# nrf9220_cellrf register map
Vendor: Nordic Semiconductor; Series: nRF92; File version: 1
CPU: CM0 r0p0, little endian, no MPU, no FPU, 2 interrupt priority bits, 33 interrupts
Registers are 32-bit, read-write, reset 0x0 unless marked. A register's access mark holds for its fields unless they carry their own. Offsets are from the block's base; [hi:lo] are bit positions; 'fields as' and 'values as' point back to an identical list.

## SX (part 1 of 3) — Ahma SX register map SX register map
Base 0x46147000
0x00 TASKS_RELOADFREQINTERNAL wo — AdPllLte will reread the frequency input signal fsFreq. This task sends a unitrigger signal to AdPllLte, which can be selected from the RELOADFREQWILLTRIGGER field
  [0] TASKS_RELOADFREQINTERNAL
    1=Trigger task
0x04 TASKS_CHANGEPHASEINTERNAL wo — AdPllLte will change the phase as given by the internal AdPllLte register PHASE_CHANGE
  [0] TASKS_CHANGEPHASEINTERNAL
    1=Trigger task
0x08 TASKS_FSSENDSETTINGS wo — Send the auto-settings to AdPllLte
  [0] TASKS_FSSENDSETTINGS
    1=Trigger task
0x0C TASKS_SOFTRESET wo — Resets all the registers which are used to send configurations/trim commands to AdPllLte
  [0] TASKS_SOFTRESET
    1=Trigger task
0x10 TASKS_STARTDMA wo — Start DMA to begin the transfer of trace data into memory
  [0] TASKS_STARTDMA
    1=Trigger task
0x14 TASKS_STOPDMA wo — Stop DMA to cease the transfer of trace data into memory
  [0] TASKS_STOPDMA
    1=Trigger task
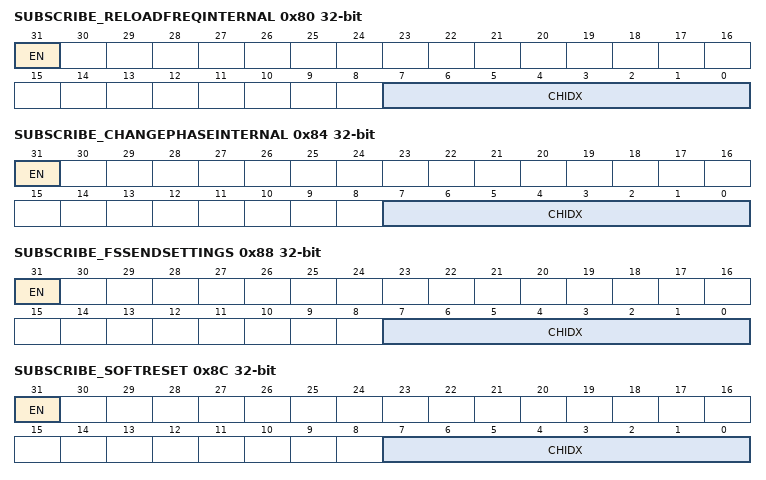
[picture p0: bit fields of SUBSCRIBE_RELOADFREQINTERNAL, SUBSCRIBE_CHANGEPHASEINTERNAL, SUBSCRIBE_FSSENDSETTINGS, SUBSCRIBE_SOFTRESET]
0x80 SUBSCRIBE_RELOADFREQINTERNAL — Subscribe configuration for task RELOADFREQINTERNAL
  [31] EN
    0=Disabled (Disable subscription); 1=Enabled (Enable subscription)
  [7:0] CHIDX — DPPI channel that task RELOADFREQINTERNAL will subscribe to
0x84 SUBSCRIBE_CHANGEPHASEINTERNAL — Subscribe configuration for task CHANGEPHASEINTERNAL
  [31] EN
    values as SUBSCRIBE_RELOADFREQINTERNAL.EN
  [7:0] CHIDX — DPPI channel that task CHANGEPHASEINTERNAL will subscribe to
0x88 SUBSCRIBE_FSSENDSETTINGS — Subscribe configuration for task FSSENDSETTINGS
  [31] EN
    values as SUBSCRIBE_RELOADFREQINTERNAL.EN
  [7:0] CHIDX — DPPI channel that task FSSENDSETTINGS will subscribe to
0x8C SUBSCRIBE_SOFTRESET — Subscribe configuration for task SOFTRESET
  [31] EN
    values as SUBSCRIBE_RELOADFREQINTERNAL.EN
  [7:0] CHIDX — DPPI channel that task SOFTRESET will subscribe to
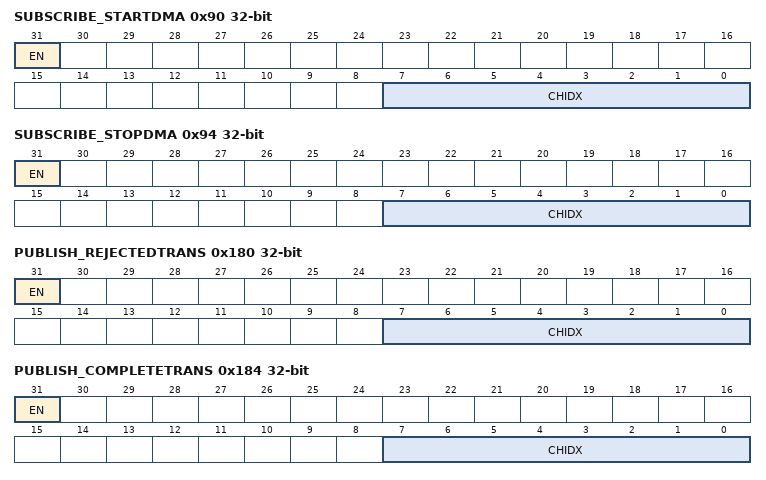
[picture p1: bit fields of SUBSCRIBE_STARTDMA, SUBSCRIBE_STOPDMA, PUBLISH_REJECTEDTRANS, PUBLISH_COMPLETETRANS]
0x90 SUBSCRIBE_STARTDMA — Subscribe configuration for task STARTDMA
  [31] EN
    values as SUBSCRIBE_RELOADFREQINTERNAL.EN
  [7:0] CHIDX — DPPI channel that task STARTDMA will subscribe to
0x94 SUBSCRIBE_STOPDMA — Subscribe configuration for task STOPDMA
  [31] EN
    values as SUBSCRIBE_RELOADFREQINTERNAL.EN
  [7:0] CHIDX — DPPI channel that task STOPDMA will subscribe to
0x100 EVENTS_REJECTEDTRANS — The command written to AdPllLte was rejected because of an ongoing transaction
  [0] EVENTS_REJECTEDTRANS
    0=NotGenerated (Event not generated); 1=Generated (Event generated)
0x104 EVENTS_COMPLETETRANS — Completed a transaction to AdPllLte successfully
  [0] EVENTS_COMPLETETRANS
    values as EVENTS_REJECTEDTRANS.EVENTS_REJECTEDTRANS
0x108 EVENTS_FAILEDTRANS — Did not successfully complete a transaction to AdPllLte (only when ENABLETIMEOUT is set in FSASYNCBUSCONF)
  [0] EVENTS_FAILEDTRANS
    values as EVENTS_REJECTEDTRANS.EVENTS_REJECTEDTRANS
0x10C EVENTS_CLOCKSTOPPEDINT — AdPllLte stopped its clock internally
  [0] EVENTS_CLOCKSTOPPEDINT
    values as EVENTS_REJECTEDTRANS.EVENTS_REJECTEDTRANS
0x110 EVENTS_COMPLETEUNITRIGGER — Unitrigger signal has successfully passed to the AdPllLte island
  [0] EVENTS_COMPLETEUNITRIGGER
    values as EVENTS_REJECTEDTRANS.EVENTS_REJECTEDTRANS
0x114 EVENTS_FAILEDUNITRIGGER — Unitrigger signal has failed to arrive in AdPllLte island (only when ENABLETIMEOUT is set in FSUNITRIGGERCONF)
  [0] EVENTS_FAILEDUNITRIGGER
    values as EVENTS_REJECTEDTRANS.EVENTS_REJECTEDTRANS
0x118 EVENTS_PLLLOCKED — AdPllLte has locked to the specified frequency
  [0] EVENTS_PLLLOCKED
    values as EVENTS_REJECTEDTRANS.EVENTS_REJECTEDTRANS
0x11C EVENTS_PLLLOCKLOST — AdPllLte has lost lock
  [0] EVENTS_PLLLOCKLOST
    values as EVENTS_REJECTEDTRANS.EVENTS_REJECTEDTRANS
0x120 EVENTS_DMAEND — DMA has filled up the result buffer in RAM.
  [0] EVENTS_DMAEND
    values as EVENTS_REJECTEDTRANS.EVENTS_REJECTEDTRANS
0x124 EVENTS_COMPLETEFSSENDSETTINGS — Sending of auto-settings to AdPllLte is successful
  [0] EVENTS_COMPLETEFSSENDSETTINGS
    values as EVENTS_REJECTEDTRANS.EVENTS_REJECTEDTRANS
0x128 EVENTS_FAILEDFSSENDSETTINGS — Sending of auto-settings to AdPlllte has failed
  [0] EVENTS_FAILEDFSSENDSETTINGS
    values as EVENTS_REJECTEDTRANS.EVENTS_REJECTEDTRANS
0x180 PUBLISH_REJECTEDTRANS — Publish configuration for event REJECTEDTRANS
  [31] EN
    0=Disabled (Disable publishing); 1=Enabled (Enable publishing)
  [7:0] CHIDX — DPPI channel that event REJECTEDTRANS will publish to
0x184 PUBLISH_COMPLETETRANS — Publish configuration for event COMPLETETRANS
  [31] EN
    values as PUBLISH_REJECTEDTRANS.EN
  [7:0] CHIDX — DPPI channel that event COMPLETETRANS will publish to
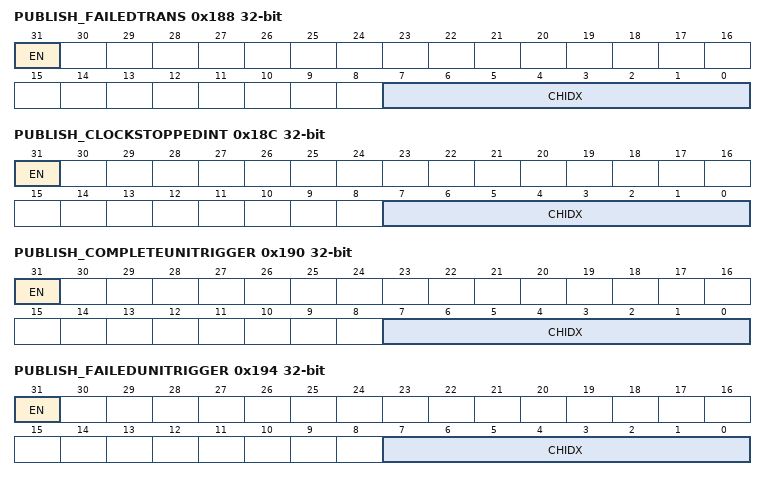
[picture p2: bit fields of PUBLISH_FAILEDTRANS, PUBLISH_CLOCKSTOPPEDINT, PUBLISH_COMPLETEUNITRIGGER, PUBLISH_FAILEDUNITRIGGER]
0x188 PUBLISH_FAILEDTRANS — Publish configuration for event FAILEDTRANS
  [31] EN
    values as PUBLISH_REJECTEDTRANS.EN
  [7:0] CHIDX — DPPI channel that event FAILEDTRANS will publish to
0x18C PUBLISH_CLOCKSTOPPEDINT — Publish configuration for event CLOCKSTOPPEDINT
  [31] EN
    values as PUBLISH_REJECTEDTRANS.EN
  [7:0] CHIDX — DPPI channel that event CLOCKSTOPPEDINT will publish to
0x190 PUBLISH_COMPLETEUNITRIGGER — Publish configuration for event COMPLETEUNITRIGGER
  [31] EN
    values as PUBLISH_REJECTEDTRANS.EN
  [7:0] CHIDX — DPPI channel that event COMPLETEUNITRIGGER will publish to
0x194 PUBLISH_FAILEDUNITRIGGER — Publish configuration for event FAILEDUNITRIGGER
  [31] EN
    values as PUBLISH_REJECTEDTRANS.EN
  [7:0] CHIDX — DPPI channel that event FAILEDUNITRIGGER will publish to
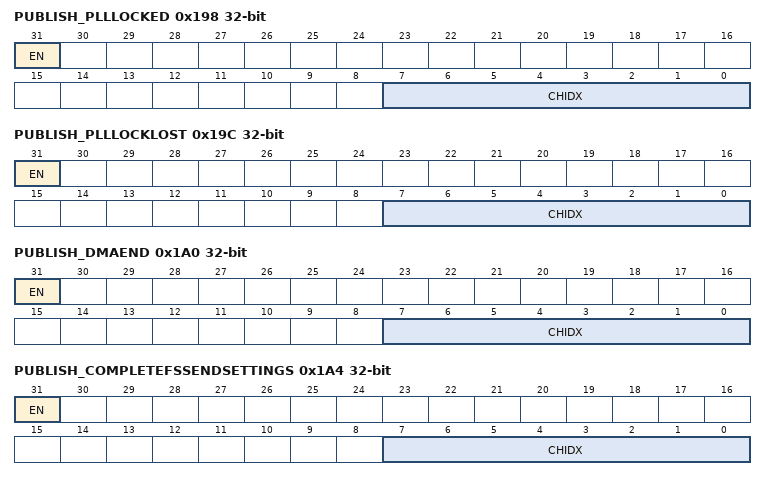
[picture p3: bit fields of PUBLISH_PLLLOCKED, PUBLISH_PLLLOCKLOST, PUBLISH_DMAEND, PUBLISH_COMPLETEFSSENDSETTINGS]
0x198 PUBLISH_PLLLOCKED — Publish configuration for event PLLLOCKED
  [31] EN
    values as PUBLISH_REJECTEDTRANS.EN
  [7:0] CHIDX — DPPI channel that event PLLLOCKED will publish to
0x19C PUBLISH_PLLLOCKLOST — Publish configuration for event PLLLOCKLOST
  [31] EN
    values as PUBLISH_REJECTEDTRANS.EN
  [7:0] CHIDX — DPPI channel that event PLLLOCKLOST will publish to
0x1A0 PUBLISH_DMAEND — Publish configuration for event DMAEND
  [31] EN
    values as PUBLISH_REJECTEDTRANS.EN
  [7:0] CHIDX — DPPI channel that event DMAEND will publish to
0x1A4 PUBLISH_COMPLETEFSSENDSETTINGS — Publish configuration for event COMPLETEFSSENDSETTINGS
  [31] EN
    values as PUBLISH_REJECTEDTRANS.EN
  [7:0] CHIDX — DPPI channel that event COMPLETEFSSENDSETTINGS will publish to
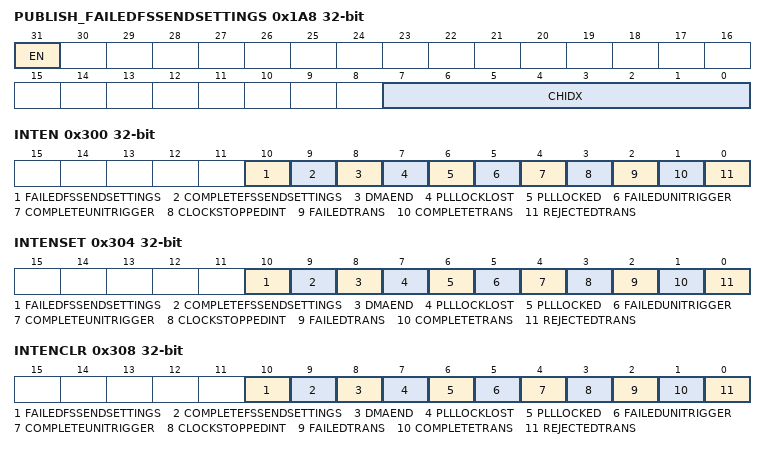
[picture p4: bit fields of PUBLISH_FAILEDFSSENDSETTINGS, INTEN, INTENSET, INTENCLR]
0x1A8 PUBLISH_FAILEDFSSENDSETTINGS — Publish configuration for event FAILEDFSSENDSETTINGS
  [31] EN
    values as PUBLISH_REJECTEDTRANS.EN
  [7:0] CHIDX — DPPI channel that event FAILEDFSSENDSETTINGS will publish to
0x300 INTEN — Enable or disable interrupt
  [all] fields
    0=Disabled; 1=Enabled
  [10] FAILEDFSSENDSETTINGS — Enable or disable interrupt for event FAILEDFSSENDSETTINGS
  [9] COMPLETEFSSENDSETTINGS — Enable or disable interrupt for event COMPLETEFSSENDSETTINGS
  [8] DMAEND — Enable or disable interrupt for event DMAEND
  [7] PLLLOCKLOST — Enable or disable interrupt for event PLLLOCKLOST
  [6] PLLLOCKED — Enable or disable interrupt for event PLLLOCKED
  [5] FAILEDUNITRIGGER — Enable or disable interrupt for event FAILEDUNITRIGGER
  [4] COMPLETEUNITRIGGER — Enable or disable interrupt for event COMPLETEUNITRIGGER
  [3] CLOCKSTOPPEDINT — Enable or disable interrupt for event CLOCKSTOPPEDINT
  [2] FAILEDTRANS — Enable or disable interrupt for event FAILEDTRANS
  [1] COMPLETETRANS — Enable or disable interrupt for event COMPLETETRANS
  [0] REJECTEDTRANS — Enable or disable interrupt for event REJECTEDTRANS
0x304 INTENSET — Enable interrupt
  [all] fields
    on read: 0=Disabled (Read: Disabled); 1=Enabled (Read: Enabled) | on write: 1=Set (Enable)
  [10] FAILEDFSSENDSETTINGS — Write '1' to enable interrupt for event FAILEDFSSENDSETTINGS
  [9] COMPLETEFSSENDSETTINGS — Write '1' to enable interrupt for event COMPLETEFSSENDSETTINGS
  [8] DMAEND — Write '1' to enable interrupt for event DMAEND
  [7] PLLLOCKLOST — Write '1' to enable interrupt for event PLLLOCKLOST
  [6] PLLLOCKED — Write '1' to enable interrupt for event PLLLOCKED
  [5] FAILEDUNITRIGGER — Write '1' to enable interrupt for event FAILEDUNITRIGGER
  [4] COMPLETEUNITRIGGER — Write '1' to enable interrupt for event COMPLETEUNITRIGGER
  [3] CLOCKSTOPPEDINT — Write '1' to enable interrupt for event CLOCKSTOPPEDINT
  [2] FAILEDTRANS — Write '1' to enable interrupt for event FAILEDTRANS
  [1] COMPLETETRANS — Write '1' to enable interrupt for event COMPLETETRANS
  [0] REJECTEDTRANS — Write '1' to enable interrupt for event REJECTEDTRANS
0x308 INTENCLR — Disable interrupt
  [all] fields
    on read: 0=Disabled (Read: Disabled); 1=Enabled (Read: Enabled) | on write: 1=Clear (Disable)
  [10] FAILEDFSSENDSETTINGS — Write '1' to disable interrupt for event FAILEDFSSENDSETTINGS
  [9] COMPLETEFSSENDSETTINGS — Write '1' to disable interrupt for event COMPLETEFSSENDSETTINGS
  [8] DMAEND — Write '1' to disable interrupt for event DMAEND
  [7] PLLLOCKLOST — Write '1' to disable interrupt for event PLLLOCKLOST
  [6] PLLLOCKED — Write '1' to disable interrupt for event PLLLOCKED
  [5] FAILEDUNITRIGGER — Write '1' to disable interrupt for event FAILEDUNITRIGGER
  [4] COMPLETEUNITRIGGER — Write '1' to disable interrupt for event COMPLETEUNITRIGGER
  [3] CLOCKSTOPPEDINT — Write '1' to disable interrupt for event CLOCKSTOPPEDINT
  [2] FAILEDTRANS — Write '1' to disable interrupt for event FAILEDTRANS
  [1] COMPLETETRANS — Write '1' to disable interrupt for event COMPLETETRANS
  [0] REJECTEDTRANS — Write '1' to disable interrupt for event REJECTEDTRANS
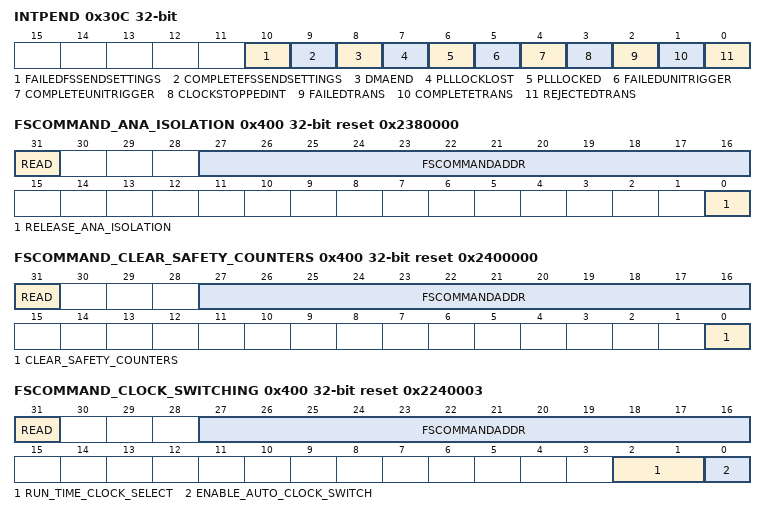
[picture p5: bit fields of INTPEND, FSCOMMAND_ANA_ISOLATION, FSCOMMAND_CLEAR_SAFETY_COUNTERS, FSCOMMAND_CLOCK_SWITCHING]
0x30C INTPEND ro — Pending interrupts
  [all] fields
    on read: 0=NotPending (Read: Not pending); 1=Pending (Read: Pending)
  [10] FAILEDFSSENDSETTINGS — Read pending status of interrupt for event FAILEDFSSENDSETTINGS
  [9] COMPLETEFSSENDSETTINGS — Read pending status of interrupt for event COMPLETEFSSENDSETTINGS
  [8] DMAEND — Read pending status of interrupt for event DMAEND
  [7] PLLLOCKLOST — Read pending status of interrupt for event PLLLOCKLOST
  [6] PLLLOCKED — Read pending status of interrupt for event PLLLOCKED
  [5] FAILEDUNITRIGGER — Read pending status of interrupt for event FAILEDUNITRIGGER
  [4] COMPLETEUNITRIGGER — Read pending status of interrupt for event COMPLETEUNITRIGGER
  [3] CLOCKSTOPPEDINT — Read pending status of interrupt for event CLOCKSTOPPEDINT
  [2] FAILEDTRANS — Read pending status of interrupt for event FAILEDTRANS
  [1] COMPLETETRANS — Read pending status of interrupt for event COMPLETETRANS
  [0] REJECTEDTRANS — Read pending status of interrupt for event REJECTEDTRANS
0x400 FSCOMMAND_ANA_ISOLATION reset 0x2380000 — Send or receive command directly to/from the AdPllLte digital island. Only write to this register when FSASYNCBUSBUSY returns 0
  [31] READ — When 1, a read transaction is initiated. When the event COMPLETETRANS is set, read back this register
  [27:16] FSCOMMANDADDR — Address for the async interface. ALWAYS 0x238.
    0x238=ANA_ISOLATION_ADDR (ALWAYS 0x238.)
  [0] RELEASE_ANA_ISOLATION — When set to 1, we drop the isolation of signals from the analog side EVEN WHEN fsStart is low
0x400 FSCOMMAND_CLEAR_SAFETY_COUNTERS reset 0x2400000 (alternate view of FSCOMMAND_ANA_ISOLATION) — Send or receive command directly to/from the AdPllLte digital island. Only write to this register when FSASYNCBUSBUSY returns 0
  [31] READ — When 1, a read transaction is initiated. When the event COMPLETETRANS is set, read back this register
  [27:16] FSCOMMANDADDR — Address for the async interface. ALWAYS 0x240.
    0x240=CLEAR_SAFETY_COUNTERS_ADDR (ALWAYS 0x240.)
  [0] CLEAR_SAFETY_COUNTERS — Clear the safety counters
0x400 FSCOMMAND_CLOCK_SWITCHING reset 0x2240003 (alternate view of FSCOMMAND_ANA_ISOLATION) — Send or receive command directly to/from the AdPllLte digital island. Only write to this register when FSASYNCBUSBUSY returns 0
  [31] READ — When 1, a read transaction is initiated. When the event COMPLETETRANS is set, read back this register
  [27:16] FSCOMMANDADDR — Address for the async interface. ALWAYS 0x224.
    0x224=CLOCK_SWITCHING_ADDR (ALWAYS 0x224.)
  [2:1] RUN_TIME_CLOCK_SELECT — Clock select for PLL runtime. 0:ck64MCore, 1:ckRetimed, 2: ckRef
  [0] ENABLE_AUTO_CLOCK_SWITCH — Enable automatic switching from ck64MCore to configurable run time clock and back
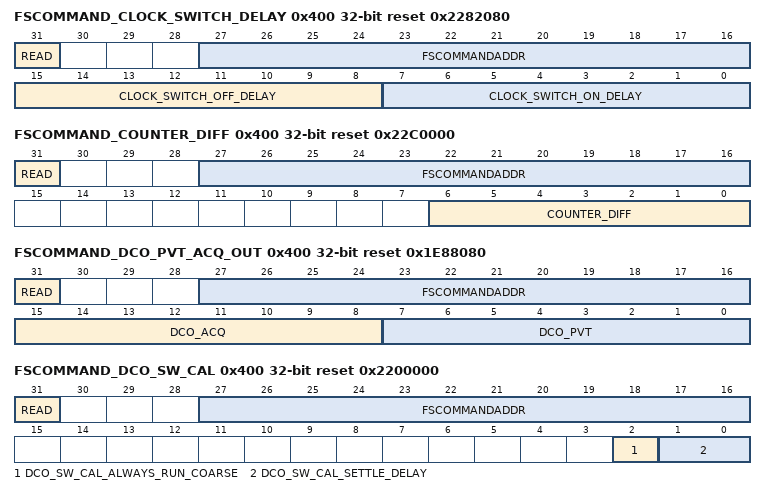
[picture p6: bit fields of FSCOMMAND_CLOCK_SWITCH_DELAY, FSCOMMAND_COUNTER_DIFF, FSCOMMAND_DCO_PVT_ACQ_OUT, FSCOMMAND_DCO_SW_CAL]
0x400 FSCOMMAND_CLOCK_SWITCH_DELAY reset 0x2282080 (alternate view of FSCOMMAND_ANA_ISOLATION) — Send or receive command directly to/from the AdPllLte digital island. Only write to this register when FSASYNCBUSBUSY returns 0
  [31] READ — When 1, a read transaction is initiated. When the event COMPLETETRANS is set, read back this register
  [27:16] FSCOMMANDADDR — Address for the async interface. ALWAYS 0x228.
    0x228=CLOCK_SWITCH_DELAY_ADDR (ALWAYS 0x228.)
  [15:8] CLOCK_SWITCH_OFF_DELAY — Number of clock cycles to wait before shutting down DCO before and switching to ck64MCore clock
  [7:0] CLOCK_SWITCH_ON_DELAY — Number of clock cycles to wait after swing calibration state before switching to ckRetimed clock
0x400 FSCOMMAND_COUNTER_DIFF reset 0x22C0000 (alternate view of FSCOMMAND_ANA_ISOLATION) — Send or receive command directly to/from the AdPllLte digital island. Only write to this register when FSASYNCBUSBUSY returns 0
  [31] READ — When 1, a read transaction is initiated. When the event COMPLETETRANS is set, read back this register
  [27:16] FSCOMMANDADDR — Address for the async interface. ALWAYS 0x22C.
    0x22C=COUNTER_DIFF_ADDR (ALWAYS 0x22C.)
  [6:0] COUNTER_DIFF — The current diff in the counter phase detect module. This number is proportional with the DCO frequency
0x400 FSCOMMAND_DCO_PVT_ACQ_OUT reset 0x1E88080 (alternate view of FSCOMMAND_ANA_ISOLATION) — Send or receive command directly to/from the AdPllLte digital island. Only write to this register when FSASYNCBUSBUSY returns 0
  [31] READ — When 1, a read transaction is initiated. When the event COMPLETETRANS is set, read back this register
  [27:16] FSCOMMANDADDR — Address for the async interface. ALWAYS 0x1E8.
    0x1E8=DCO_PVT_ACQ_OUT_ADDR (ALWAYS 0x1E8.)
  [15:8] DCO_ACQ — Read the current ACQ bank control word
  [7:0] DCO_PVT — Read the current PVT bank control word
0x400 FSCOMMAND_DCO_SW_CAL reset 0x2200000 (alternate view of FSCOMMAND_ANA_ISOLATION) — Send or receive command directly to/from the AdPllLte digital island. Only write to this register when FSASYNCBUSBUSY returns 0
  [31] READ — When 1, a read transaction is initiated. When the event COMPLETETRANS is set, read back this register
  [27:16] FSCOMMANDADDR — Address for the async interface. ALWAYS 0x220.
    0x220=DCO_SW_CAL_ADDR (ALWAYS 0x220.)
  [2] DCO_SW_CAL_ALWAYS_RUN_COARSE — Always rerun coarse swing calibration before fine swing calibration
  [1:0] DCO_SW_CAL_SETTLE_DELAY — DCO swing calibration settling delay after calibration value is updated
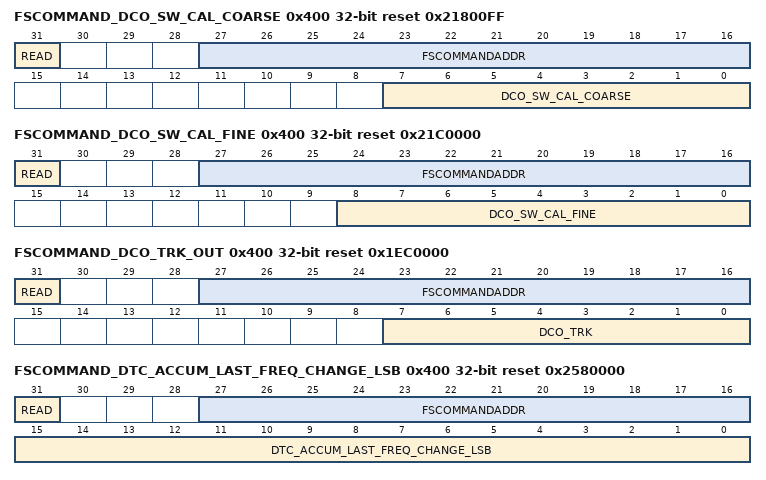
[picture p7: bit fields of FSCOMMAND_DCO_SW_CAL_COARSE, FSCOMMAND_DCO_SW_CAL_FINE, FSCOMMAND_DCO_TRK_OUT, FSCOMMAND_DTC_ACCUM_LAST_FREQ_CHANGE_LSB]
0x400 FSCOMMAND_DCO_SW_CAL_COARSE reset 0x21800FF (alternate view of FSCOMMAND_ANA_ISOLATION) — Send or receive command directly to/from the AdPllLte digital island. Only write to this register when FSASYNCBUSBUSY returns 0
  [31] READ — When 1, a read transaction is initiated. When the event COMPLETETRANS is set, read back this register
  [27:16] FSCOMMANDADDR — Address for the async interface. ALWAYS 0x218.
    0x218=DCO_SW_CAL_COARSE_ADDR (ALWAYS 0x218.)
  [7:0] DCO_SW_CAL_COARSE — The current DCO swing coarse calibration value
0x400 FSCOMMAND_DCO_SW_CAL_FINE reset 0x21C0000 (alternate view of FSCOMMAND_ANA_ISOLATION) — Send or receive command directly to/from the AdPllLte digital island. Only write to this register when FSASYNCBUSBUSY returns 0
  [31] READ — When 1, a read transaction is initiated. When the event COMPLETETRANS is set, read back this register
  [27:16] FSCOMMANDADDR — Address for the async interface. ALWAYS 0x21C.
    0x21C=DCO_SW_CAL_FINE_ADDR (ALWAYS 0x21C.)
  [8:0] DCO_SW_CAL_FINE — The current DCO swing fine calibration value
0x400 FSCOMMAND_DCO_TRK_OUT reset 0x1EC0000 (alternate view of FSCOMMAND_ANA_ISOLATION) — Send or receive command directly to/from the AdPllLte digital island. Only write to this register when FSASYNCBUSBUSY returns 0
  [31] READ — When 1, a read transaction is initiated. When the event COMPLETETRANS is set, read back this register
  [27:16] FSCOMMANDADDR — Address for the async interface. ALWAYS 0x1EC.
    0x1EC=DCO_TRK_OUT_ADDR (ALWAYS 0x1EC.)
  [7:0] DCO_TRK — Read the current TRK bank control word
0x400 FSCOMMAND_DTC_ACCUM_LAST_FREQ_CHANGE_LSB reset 0x2580000 (alternate view of FSCOMMAND_ANA_ISOLATION) — Send or receive command directly to/from the AdPllLte digital island. Only write to this register when FSASYNCBUSBUSY returns 0
  [31] READ — When 1, a read transaction is initiated. When the event COMPLETETRANS is set, read back this register
  [27:16] FSCOMMANDADDR — Address for the async interface. ALWAYS 0x258.
    0x258=DTC_ACCUM_LAST_FREQ_CHANGE_LSB_ADDR (ALWAYS 0x258.)
  [15:0] DTC_ACCUM_LAST_FREQ_CHANGE_LSB — The accumulator value the last time the frequency was changed or when SAMPLE_DTC_ACCUM_NOW is written to
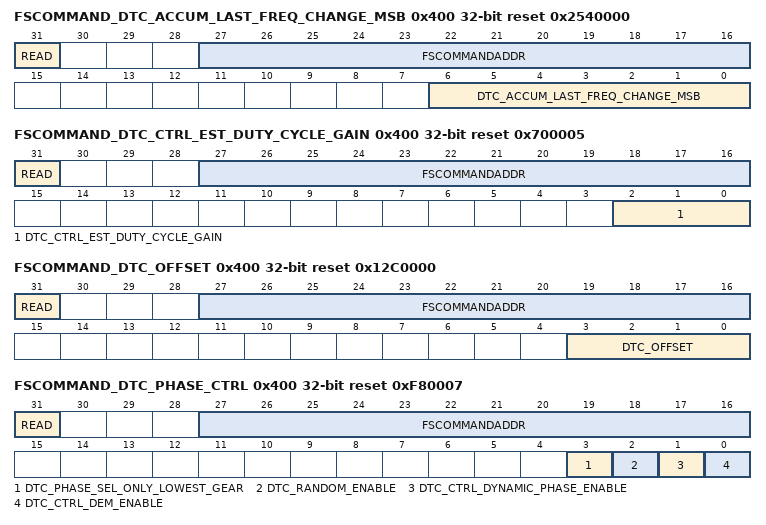
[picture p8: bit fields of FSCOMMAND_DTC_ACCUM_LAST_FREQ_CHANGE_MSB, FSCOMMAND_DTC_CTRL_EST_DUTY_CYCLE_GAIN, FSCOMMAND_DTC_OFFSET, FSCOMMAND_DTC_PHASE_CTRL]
0x400 FSCOMMAND_DTC_ACCUM_LAST_FREQ_CHANGE_MSB reset 0x2540000 (alternate view of FSCOMMAND_ANA_ISOLATION) — Send or receive command directly to/from the AdPllLte digital island. Only write to this register when FSASYNCBUSBUSY returns 0
  [31] READ — When 1, a read transaction is initiated. When the event COMPLETETRANS is set, read back this register
  [27:16] FSCOMMANDADDR — Address for the async interface. ALWAYS 0x254.
    0x254=DTC_ACCUM_LAST_FREQ_CHANGE_MSB_ADDR (ALWAYS 0x254.)
  [6:0] DTC_ACCUM_LAST_FREQ_CHANGE_MSB — The accumulator value the last time the frequency was changed or when SAMPLE_DTC_ACCUM_NOW is written to
0x400 FSCOMMAND_DTC_CTRL_EST_DUTY_CYCLE_GAIN reset 0x700005 (alternate view of FSCOMMAND_ANA_ISOLATION) — Send or receive command directly to/from the AdPllLte digital island. Only write to this register when FSASYNCBUSBUSY returns 0
  [31] READ — When 1, a read transaction is initiated. When the event COMPLETETRANS is set, read back this register
  [27:16] FSCOMMANDADDR — Address for the async interface. ALWAYS 0x70.
    112=DTC_CTRL_EST_DUTY_CYCLE_GAIN_ADDR (ALWAYS 0x70.)
  [2:0] DTC_CTRL_EST_DUTY_CYCLE_GAIN — How much impact the estimated duty cycle gain should have on the DTC compensation (shifted by this value to the left). Used in DtcComp
0x400 FSCOMMAND_DTC_OFFSET reset 0x12C0000 (alternate view of FSCOMMAND_ANA_ISOLATION) — Send or receive command directly to/from the AdPllLte digital island. Only write to this register when FSASYNCBUSBUSY returns 0
  [31] READ — When 1, a read transaction is initiated. When the event COMPLETETRANS is set, read back this register
  [27:16] FSCOMMANDADDR — Address for the async interface. ALWAYS 0x12C.
    0x12C=DTC_OFFSET_ADDR (ALWAYS 0x12C.)
  [3:0] DTC_OFFSET — Add an offset to the DTC control value
0x400 FSCOMMAND_DTC_PHASE_CTRL reset 0xF80007 (alternate view of FSCOMMAND_ANA_ISOLATION) — Send or receive command directly to/from the AdPllLte digital island. Only write to this register when FSASYNCBUSBUSY returns 0
  [31] READ — When 1, a read transaction is initiated. When the event COMPLETETRANS is set, read back this register
  [27:16] FSCOMMANDADDR — Address for the async interface. ALWAYS 0xF8.
    248=DTC_PHASE_CTRL_ADDR (ALWAYS 0xF8.)
  [3] DTC_PHASE_SEL_ONLY_LOWEST_GEAR — Phase select randomization begins only when TRK uses the lowest gear.
  [2] DTC_RANDOM_ENABLE — Enable randomization of the phase selected from the MUX following the divider.
  [1] DTC_CTRL_DYNAMIC_PHASE_ENABLE — Selects whether the DCO phase should be alternated or not. If 0, neither randomized shift and predictable shift happens. If 1, and dtcRandomEnable == 0, it alternates regularly between the two phases
  [0] DTC_CTRL_DEM_ENABLE — For enabling dynamic element matching. Used in DtcCtrl/DtcDem
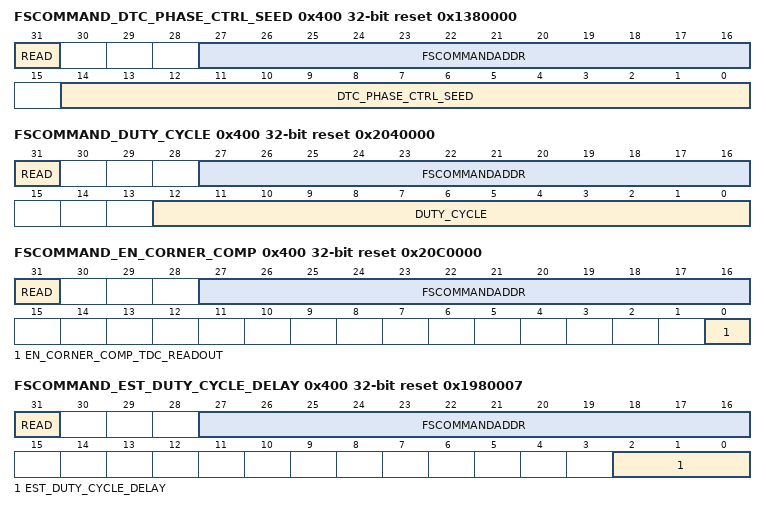
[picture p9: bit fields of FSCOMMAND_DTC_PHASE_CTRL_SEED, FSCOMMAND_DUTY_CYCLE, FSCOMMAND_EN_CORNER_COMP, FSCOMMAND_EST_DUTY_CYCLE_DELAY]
0x400 FSCOMMAND_DTC_PHASE_CTRL_SEED reset 0x1380000 (alternate view of FSCOMMAND_ANA_ISOLATION) — Send or receive command directly to/from the AdPllLte digital island. Only write to this register when FSASYNCBUSBUSY returns 0
  [31] READ — When 1, a read transaction is initiated. When the event COMPLETETRANS is set, read back this register
  [27:16] FSCOMMANDADDR — Address for the async interface. ALWAYS 0x138.
    0x138=DTC_PHASE_CTRL_SEED_ADDR (ALWAYS 0x138.)
  [14:0] DTC_PHASE_CTRL_SEED — The LFSR seed value for DtcPhaseCtrl
0x400 FSCOMMAND_DUTY_CYCLE reset 0x2040000 (alternate view of FSCOMMAND_ANA_ISOLATION) — Send or receive command directly to/from the AdPllLte digital island. Only write to this register when FSASYNCBUSBUSY returns 0
  [31] READ — When 1, a read transaction is initiated. When the event COMPLETETRANS is set, read back this register
  [27:16] FSCOMMANDADDR — Address for the async interface. ALWAYS 0x204.
    0x204=DUTY_CYCLE_ADDR (ALWAYS 0x204.)
  [12:0] DUTY_CYCLE — Read the current duty cycle estimate
0x400 FSCOMMAND_EN_CORNER_COMP reset 0x20C0000 (alternate view of FSCOMMAND_ANA_ISOLATION) — Send or receive command directly to/from the AdPllLte digital island. Only write to this register when FSASYNCBUSBUSY returns 0
  [31] READ — When 1, a read transaction is initiated. When the event COMPLETETRANS is set, read back this register
  [27:16] FSCOMMANDADDR — Address for the async interface. ALWAYS 0x20C.
    0x20C=EN_CORNER_COMP_ADDR (ALWAYS 0x20C.)
  [0] EN_CORNER_COMP_TDC_READOUT — Enable corner compensation for the loopGain for the TRK bank control (based on PVT control value relative to expected)
0x400 FSCOMMAND_EST_DUTY_CYCLE_DELAY reset 0x1980007 (alternate view of FSCOMMAND_ANA_ISOLATION) — Send or receive command directly to/from the AdPllLte digital island. Only write to this register when FSASYNCBUSBUSY returns 0
  [31] READ — When 1, a read transaction is initiated. When the event COMPLETETRANS is set, read back this register
  [27:16] FSCOMMANDADDR — Address for the async interface. ALWAYS 0x198.
    0x198=EST_DUTY_CYCLE_DELAY_ADDR (ALWAYS 0x198.)
  [2:0] EST_DUTY_CYCLE_DELAY — How many cycles to delay i_s_phase_edge and i_s_dtc_sign at the input of the duty-cycle estimation module
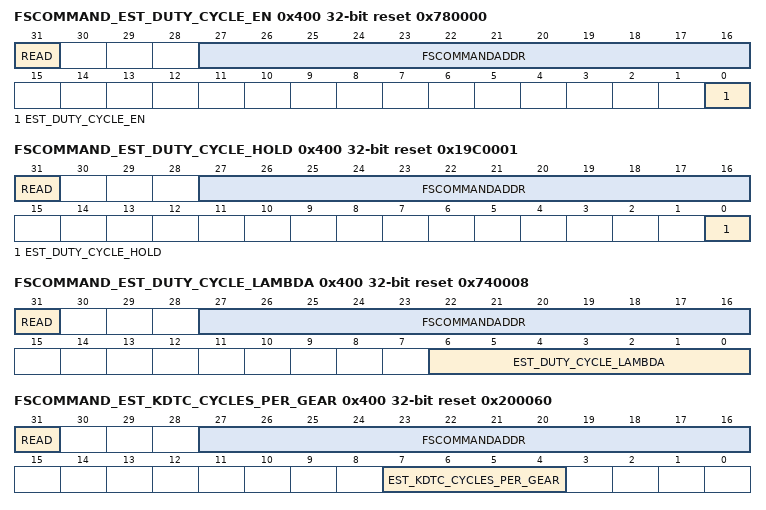
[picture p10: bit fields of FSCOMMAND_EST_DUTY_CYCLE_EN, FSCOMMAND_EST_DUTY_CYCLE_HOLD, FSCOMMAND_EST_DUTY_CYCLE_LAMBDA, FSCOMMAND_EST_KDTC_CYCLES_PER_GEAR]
0x400 FSCOMMAND_EST_DUTY_CYCLE_EN reset 0x780000 (alternate view of FSCOMMAND_ANA_ISOLATION) — Send or receive command directly to/from the AdPllLte digital island. Only write to this register when FSASYNCBUSBUSY returns 0
  [31] READ — When 1, a read transaction is initiated. When the event COMPLETETRANS is set, read back this register
  [27:16] FSCOMMANDADDR — Address for the async interface. ALWAYS 0x78.
    120=EST_DUTY_CYCLE_EN_ADDR (ALWAYS 0x78.)
  [0] EST_DUTY_CYCLE_EN — Enable duty cycle calibration. When 0, we do not compensate anything in DtcCtrl
0x400 FSCOMMAND_EST_DUTY_CYCLE_HOLD reset 0x19C0001 (alternate view of FSCOMMAND_ANA_ISOLATION) — Send or receive command directly to/from the AdPllLte digital island. Only write to this register when FSASYNCBUSBUSY returns 0
  [31] READ — When 1, a read transaction is initiated. When the event COMPLETETRANS is set, read back this register
  [27:16] FSCOMMANDADDR — Address for the async interface. ALWAYS 0x19C.
    0x19C=EST_DUTY_CYCLE_HOLD_ADDR (ALWAYS 0x19C.)
  [0] EST_DUTY_CYCLE_HOLD — Whether to remember the duty-cycle estimation value from one procedure to the next. (provided that the asynchronous reset is not set)
0x400 FSCOMMAND_EST_DUTY_CYCLE_LAMBDA reset 0x740008 (alternate view of FSCOMMAND_ANA_ISOLATION) — Send or receive command directly to/from the AdPllLte digital island. Only write to this register when FSASYNCBUSBUSY returns 0
  [31] READ — When 1, a read transaction is initiated. When the event COMPLETETRANS is set, read back this register
  [27:16] FSCOMMANDADDR — Address for the async interface. ALWAYS 0x74.
    116=EST_DUTY_CYCLE_LAMBDA_ADDR (ALWAYS 0x74.)
  [6:0] EST_DUTY_CYCLE_LAMBDA — The alpha value for the IIR filter in EstDutycycle
0x400 FSCOMMAND_EST_KDTC_CYCLES_PER_GEAR reset 0x200060 (alternate view of FSCOMMAND_ANA_ISOLATION) — Send or receive command directly to/from the AdPllLte digital island. Only write to this register when FSASYNCBUSBUSY returns 0
  [31] READ — When 1, a read transaction is initiated. When the event COMPLETETRANS is set, read back this register
  [27:16] FSCOMMANDADDR — Address for the async interface. ALWAYS 0x20.
    32=EST_KDTC_CYCLES_PER_GEAR_ADDR (ALWAYS 0x20.)
  [7:4] EST_KDTC_CYCLES_PER_GEAR — Number of cycles to be at one gear setting in EstKdtc (multiplied by 16)
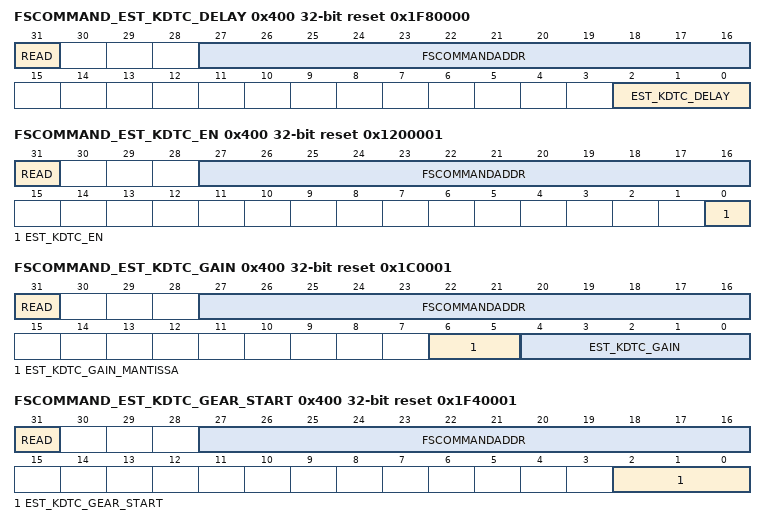
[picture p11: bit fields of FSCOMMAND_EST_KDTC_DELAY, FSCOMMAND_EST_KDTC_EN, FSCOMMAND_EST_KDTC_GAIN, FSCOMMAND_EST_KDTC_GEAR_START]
0x400 FSCOMMAND_EST_KDTC_DELAY reset 0x1F80000 (alternate view of FSCOMMAND_ANA_ISOLATION) — Send or receive command directly to/from the AdPllLte digital island. Only write to this register when FSASYNCBUSBUSY returns 0
  [31] READ — When 1, a read transaction is initiated. When the event COMPLETETRANS is set, read back this register
  [27:16] FSCOMMANDADDR — Address for the async interface. ALWAYS 0x1F8.
    0x1F8=EST_KDTC_DELAY_ADDR (ALWAYS 0x1F8.)
  [2:0] EST_KDTC_DELAY — Delay of phr_frac to align with phe_frac
0x400 FSCOMMAND_EST_KDTC_EN reset 0x1200001 (alternate view of FSCOMMAND_ANA_ISOLATION) — Send or receive command directly to/from the AdPllLte digital island. Only write to this register when FSASYNCBUSBUSY returns 0
  [31] READ — When 1, a read transaction is initiated. When the event COMPLETETRANS is set, read back this register
  [27:16] FSCOMMANDADDR — Address for the async interface. ALWAYS 0x120.
    0x120=EST_KDTC_EN_ADDR (ALWAYS 0x120.)
  [0] EST_KDTC_EN — Enable estimation of kDTC
0x400 FSCOMMAND_EST_KDTC_GAIN reset 0x1C0001 (alternate view of FSCOMMAND_ANA_ISOLATION) — Send or receive command directly to/from the AdPllLte digital island. Only write to this register when FSASYNCBUSBUSY returns 0
  [31] READ — When 1, a read transaction is initiated. When the event COMPLETETRANS is set, read back this register
  [27:16] FSCOMMANDADDR — Address for the async interface. ALWAYS 0x1C.
    28=EST_KDTC_GAIN_ADDR (ALWAYS 0x1C.)
  [6:5] EST_KDTC_GAIN_MANTISSA — The gain in the estimator loop for kDTC. Used in EstKdtc only
  [4:0] EST_KDTC_GAIN — The gain in the estimator loop for kDTC. Used in EstKdtc only
0x400 FSCOMMAND_EST_KDTC_GEAR_START reset 0x1F40001 (alternate view of FSCOMMAND_ANA_ISOLATION) — Send or receive command directly to/from the AdPllLte digital island. Only write to this register when FSASYNCBUSBUSY returns 0
  [31] READ — When 1, a read transaction is initiated. When the event COMPLETETRANS is set, read back this register
  [27:16] FSCOMMANDADDR — Address for the async interface. ALWAYS 0x1F4.
    0x1F4=EST_KDTC_GEAR_START_ADDR (ALWAYS 0x1F4.)
  [2:0] EST_KDTC_GEAR_START — The start value for the gear factor in EstKDTC
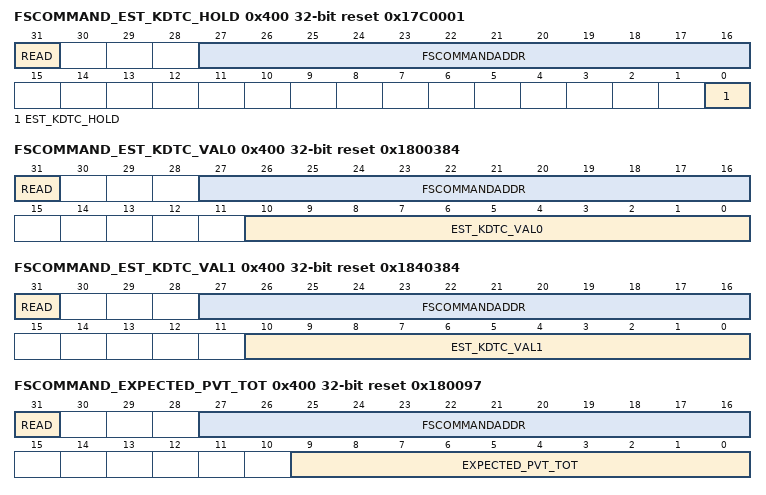
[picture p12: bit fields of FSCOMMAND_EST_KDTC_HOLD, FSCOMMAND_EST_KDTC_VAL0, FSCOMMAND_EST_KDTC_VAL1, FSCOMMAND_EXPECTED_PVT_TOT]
0x400 FSCOMMAND_EST_KDTC_HOLD reset 0x17C0001 (alternate view of FSCOMMAND_ANA_ISOLATION) — Send or receive command directly to/from the AdPllLte digital island. Only write to this register when FSASYNCBUSBUSY returns 0
  [31] READ — When 1, a read transaction is initiated. When the event COMPLETETRANS is set, read back this register
  [27:16] FSCOMMANDADDR — Address for the async interface. ALWAYS 0x17C.
    0x17C=EST_KDTC_HOLD_ADDR (ALWAYS 0x17C.)
  [0] EST_KDTC_HOLD — Store the EstKdtc value from one round to the next (as long as asynchronous reset is not asserted)
0x400 FSCOMMAND_EST_KDTC_VAL0 reset 0x1800384 (alternate view of FSCOMMAND_ANA_ISOLATION) — Send or receive command directly to/from the AdPllLte digital island. Only write to this register when FSASYNCBUSBUSY returns 0
  [31] READ — When 1, a read transaction is initiated. When the event COMPLETETRANS is set, read back this register
  [27:16] FSCOMMANDADDR — Address for the async interface. ALWAYS 0x180.
    0x180=EST_KDTC_VAL0_ADDR (ALWAYS 0x180.)
  [10:0] EST_KDTC_VAL0 — Default start value for KDTC before compensating for PVT and ACQ setting. Also, used in fast frequency jumps with respect to frequency 0
0x400 FSCOMMAND_EST_KDTC_VAL1 reset 0x1840384 (alternate view of FSCOMMAND_ANA_ISOLATION) — Send or receive command directly to/from the AdPllLte digital island. Only write to this register when FSASYNCBUSBUSY returns 0
  [31] READ — When 1, a read transaction is initiated. When the event COMPLETETRANS is set, read back this register
  [27:16] FSCOMMANDADDR — Address for the async interface. ALWAYS 0x184.
    0x184=EST_KDTC_VAL1_ADDR (ALWAYS 0x184.)
  [10:0] EST_KDTC_VAL1 — The start value for KDTC before compensating for PVT and ACQ setting which is only used in fast frequency jumps with respect to frequency 1
0x400 FSCOMMAND_EXPECTED_PVT_TOT reset 0x180097 (alternate view of FSCOMMAND_ANA_ISOLATION) — Send or receive command directly to/from the AdPllLte digital island. Only write to this register when FSASYNCBUSBUSY returns 0
  [31] READ — When 1, a read transaction is initiated. When the event COMPLETETRANS is set, read back this register
  [27:16] FSCOMMANDADDR — Address for the async interface. ALWAYS 0x18.
    24=EXPECTED_PVT_TOT_ADDR (ALWAYS 0x18.)
  [9:0] EXPECTED_PVT_TOT — The ratio between PVT and the total cap ratio. Used for Estkdtc and TdcReadout
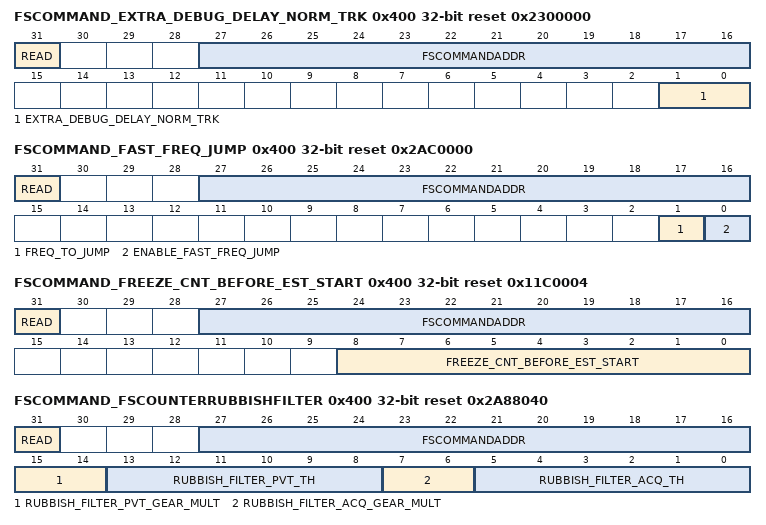
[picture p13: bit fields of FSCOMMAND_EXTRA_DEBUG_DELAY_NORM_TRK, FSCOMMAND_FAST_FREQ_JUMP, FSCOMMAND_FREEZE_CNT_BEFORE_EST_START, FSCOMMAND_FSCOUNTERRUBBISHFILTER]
0x400 FSCOMMAND_EXTRA_DEBUG_DELAY_NORM_TRK reset 0x2300000 (alternate view of FSCOMMAND_ANA_ISOLATION) — Send or receive command directly to/from the AdPllLte digital island. Only write to this register when FSASYNCBUSBUSY returns 0
  [31] READ — When 1, a read transaction is initiated. When the event COMPLETETRANS is set, read back this register
  [27:16] FSCOMMANDADDR — Address for the async interface. ALWAYS 0x230.
    0x230=EXTRA_DEBUG_DELAY_NORM_TRK_ADDR (ALWAYS 0x230.)
  [1:0] EXTRA_DEBUG_DELAY_NORM_TRK — Add even more delay in the Norm TRK loop to test how it impacts the loop. This is a debug backdoor only.
0x400 FSCOMMAND_FAST_FREQ_JUMP reset 0x2AC0000 (alternate view of FSCOMMAND_ANA_ISOLATION) — Send or receive command directly to/from the AdPllLte digital island. Only write to this register when FSASYNCBUSBUSY returns 0
  [31] READ — When 1, a read transaction is initiated. When the event COMPLETETRANS is set, read back this register
  [27:16] FSCOMMANDADDR — Address for the async interface. ALWAYS 0x2AC.
    0x2AC=FAST_FREQ_JUMP_ADDR (ALWAYS 0x2AC.)
  [1] FREQ_TO_JUMP — Select which frequency to jump to. frequency 0 or frequency 1
  [0] ENABLE_FAST_FREQ_JUMP — Enable fast frequency jump between two frequencies
0x400 FSCOMMAND_FREEZE_CNT_BEFORE_EST_START reset 0x11C0004 (alternate view of FSCOMMAND_ANA_ISOLATION) — Send or receive command directly to/from the AdPllLte digital island. Only write to this register when FSASYNCBUSBUSY returns 0
  [31] READ — When 1, a read transaction is initiated. When the event COMPLETETRANS is set, read back this register
  [27:16] FSCOMMANDADDR — Address for the async interface. ALWAYS 0x11C.
    0x11C=FREEZE_CNT_BEFORE_EST_START_ADDR (ALWAYS 0x11C.)
  [8:0] FREEZE_CNT_BEFORE_EST_START — Initialization value for freeze counter. EstKdtc etc is started after this number of cycles after a cold start
0x400 FSCOMMAND_FSCOUNTERRUBBISHFILTER reset 0x2A88040 (alternate view of FSCOMMAND_ANA_ISOLATION) — Send or receive command directly to/from the AdPllLte digital island. Only write to this register when FSASYNCBUSBUSY returns 0
  [31] READ — When 1, a read transaction is initiated. When the event COMPLETETRANS is set, read back this register
  [27:16] FSCOMMANDADDR — Address for the async interface. ALWAYS 0x2A8.
    0x2A8=FSCOUNTERRUBBISHFILTER_ADDR (ALWAYS 0x2A8.)
  [15:14] RUBBISH_FILTER_PVT_GEAR_MULT — If 0, the rubbish filter threshold for faster PVT gears is the same as rubbishFilterPvtTh. If 1, it is rubbishFilterPvtTh*2, If 2, it is rubbishFilterPvtTh*3 etc.
  [13:8] RUBBISH_FILTER_PVT_TH — If 0, rubbish filter for PVT is disabled. This is the maximum +- value to allow from the counter when in the ACQ calibration state
  [7:6] RUBBISH_FILTER_ACQ_GEAR_MULT — If 0, the rubbish filter threshold for faster ACQ gears is the same as rubbishFilterAcqTh. If 1, it is rubbishFilterAcqTh*2, If 2, it is rubbishFilterAcqTh*3 etc.
  [5:0] RUBBISH_FILTER_ACQ_TH — If 0, rubbish filter for ACQ is disabled. This is the maximum +- value to allow from the counter when in the ACQ calibration state gear 1
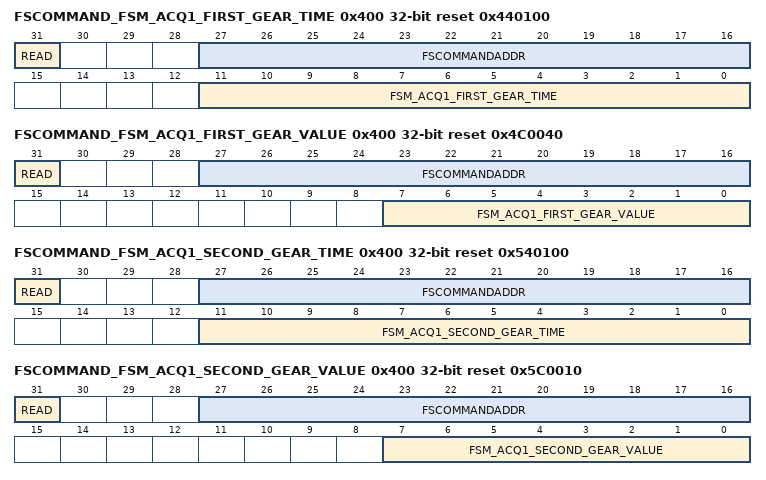
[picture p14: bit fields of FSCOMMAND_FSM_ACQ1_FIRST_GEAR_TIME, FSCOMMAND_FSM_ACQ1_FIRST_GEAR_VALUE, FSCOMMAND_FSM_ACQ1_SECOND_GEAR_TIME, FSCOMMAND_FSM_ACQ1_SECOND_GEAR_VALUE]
0x400 FSCOMMAND_FSM_ACQ1_FIRST_GEAR_TIME reset 0x440100 (alternate view of FSCOMMAND_ANA_ISOLATION) — Send or receive command directly to/from the AdPllLte digital island. Only write to this register when FSASYNCBUSBUSY returns 0
  [31] READ — When 1, a read transaction is initiated. When the event COMPLETETRANS is set, read back this register
  [27:16] FSCOMMANDADDR — Address for the async interface. ALWAYS 0x44.
    68=FSM_ACQ1_FIRST_GEAR_TIME_ADDR (ALWAYS 0x44.)
  [11:0] FSM_ACQ1_FIRST_GEAR_TIME — The number of cycles before we change gear in ACQ1 state the first time. Used in AdPllFsm
0x400 FSCOMMAND_FSM_ACQ1_FIRST_GEAR_VALUE reset 0x4C0040 (alternate view of FSCOMMAND_ANA_ISOLATION) — Send or receive command directly to/from the AdPllLte digital island. Only write to this register when FSASYNCBUSBUSY returns 0
  [31] READ — When 1, a read transaction is initiated. When the event COMPLETETRANS is set, read back this register
  [27:16] FSCOMMANDADDR — Address for the async interface. ALWAYS 0x4C.
    76=FSM_ACQ1_FIRST_GEAR_VALUE_ADDR (ALWAYS 0x4C.)
  [7:0] FSM_ACQ1_FIRST_GEAR_VALUE — The first gear value in ACQ1 state. If changed while running, and it becomes lower than the current value driven from AdPllFsm, the lowest value will be used.
0x400 FSCOMMAND_FSM_ACQ1_SECOND_GEAR_TIME reset 0x540100 (alternate view of FSCOMMAND_ANA_ISOLATION) — Send or receive command directly to/from the AdPllLte digital island. Only write to this register when FSASYNCBUSBUSY returns 0
  [31] READ — When 1, a read transaction is initiated. When the event COMPLETETRANS is set, read back this register
  [27:16] FSCOMMANDADDR — Address for the async interface. ALWAYS 0x54.
    84=FSM_ACQ1_SECOND_GEAR_TIME_ADDR (ALWAYS 0x54.)
  [11:0] FSM_ACQ1_SECOND_GEAR_TIME — The number of cycles before we change gear in ACQ1 the second time. Used in AdPllFsm
0x400 FSCOMMAND_FSM_ACQ1_SECOND_GEAR_VALUE reset 0x5C0010 (alternate view of FSCOMMAND_ANA_ISOLATION) — Send or receive command directly to/from the AdPllLte digital island. Only write to this register when FSASYNCBUSBUSY returns 0
  [31] READ — When 1, a read transaction is initiated. When the event COMPLETETRANS is set, read back this register
  [27:16] FSCOMMANDADDR — Address for the async interface. ALWAYS 0x5C.
    92=FSM_ACQ1_SECOND_GEAR_VALUE_ADDR (ALWAYS 0x5C.)
  [7:0] FSM_ACQ1_SECOND_GEAR_VALUE — The second gear value in ACQ1 state
0x400 FSCOMMAND_FSM_ACQ1_TOTAL_TIME reset 0x1100300 (alternate view of FSCOMMAND_ANA_ISOLATION) — Send or receive command directly to/from the AdPllLte digital island. Only write to this register when FSASYNCBUSBUSY returns 0
  [31] READ — When 1, a read transaction is initiated. When the event COMPLETETRANS is set, read back this register
  [27:16] FSCOMMANDADDR — Address for the async interface. ALWAYS 0x110.
    0x110=FSM_ACQ1_TOTAL_TIME_ADDR (ALWAYS 0x110.)
  [13:3] FSM_ACQ1_TOTAL_TIME — The total time to be in the ACQ1 state (multiplied by 8)
0x400 FSCOMMAND_FSM_ACQ2_FIRST_GEAR_TIME reset 0x480100 (alternate view of FSCOMMAND_ANA_ISOLATION) — Send or receive command directly to/from the AdPllLte digital island. Only write to this register when FSASYNCBUSBUSY returns 0
  [31] READ — When 1, a read transaction is initiated. When the event COMPLETETRANS is set, read back this register
  [27:16] FSCOMMANDADDR — Address for the async interface. ALWAYS 0x48.
    72=FSM_ACQ2_FIRST_GEAR_TIME_ADDR (ALWAYS 0x48.)
  [11:0] FSM_ACQ2_FIRST_GEAR_TIME — The number of cycles before we change gear in ACQ2 state the first time. Used in AdPllFsm
0x400 FSCOMMAND_FSM_ACQ2_FIRST_GEAR_VALUE reset 0x500040 (alternate view of FSCOMMAND_ANA_ISOLATION) — Send or receive command directly to/from the AdPllLte digital island. Only write to this register when FSASYNCBUSBUSY returns 0
  [31] READ — When 1, a read transaction is initiated. When the event COMPLETETRANS is set, read back this register
  [27:16] FSCOMMANDADDR — Address for the async interface. ALWAYS 0x50.
    80=FSM_ACQ2_FIRST_GEAR_VALUE_ADDR (ALWAYS 0x50.)
  [7:0] FSM_ACQ2_FIRST_GEAR_VALUE — The first gear value in ACQ2 state. If changed while running, and it becomes lower than the current value driven from AdPllFsm, the lowest value will be used.
0x400 FSCOMMAND_FSM_ACQ2_SECOND_GEAR_TIME reset 0x580100 (alternate view of FSCOMMAND_ANA_ISOLATION) — Send or receive command directly to/from the AdPllLte digital island. Only write to this register when FSASYNCBUSBUSY returns 0
  [31] READ — When 1, a read transaction is initiated. When the event COMPLETETRANS is set, read back this register
  [27:16] FSCOMMANDADDR — Address for the async interface. ALWAYS 0x58.
    88=FSM_ACQ2_SECOND_GEAR_TIME_ADDR (ALWAYS 0x58.)
  [11:0] FSM_ACQ2_SECOND_GEAR_TIME — The number of cycles before we change gear in ACQ2 the second time. Used in AdPllFsm
0x400 FSCOMMAND_FSM_ACQ2_SECOND_GEAR_VALUE reset 0x600010 (alternate view of FSCOMMAND_ANA_ISOLATION) — Send or receive command directly to/from the AdPllLte digital island. Only write to this register when FSASYNCBUSBUSY returns 0
  [31] READ — When 1, a read transaction is initiated. When the event COMPLETETRANS is set, read back this register
  [27:16] FSCOMMANDADDR — Address for the async interface. ALWAYS 0x60.
    96=FSM_ACQ2_SECOND_GEAR_VALUE_ADDR (ALWAYS 0x60.)
  [7:0] FSM_ACQ2_SECOND_GEAR_VALUE — The second gear value in ACQ2 state
0x400 FSCOMMAND_FSM_ACQ2_TOTAL_TIME reset 0x1140300 (alternate view of FSCOMMAND_ANA_ISOLATION) — Send or receive command directly to/from the AdPllLte digital island. Only write to this register when FSASYNCBUSBUSY returns 0
  [31] READ — When 1, a read transaction is initiated. When the event COMPLETETRANS is set, read back this register
  [27:16] FSCOMMANDADDR — Address for the async interface. ALWAYS 0x114.
    0x114=FSM_ACQ2_TOTAL_TIME_ADDR (ALWAYS 0x114.)
  [13:3] FSM_ACQ2_TOTAL_TIME — The total time to be in the ACQ2 state (multiplied by 8)
0x400 FSCOMMAND_FSM_PVT1_MODE reset 0x8400C0 (alternate view of FSCOMMAND_ANA_ISOLATION) — Send or receive command directly to/from the AdPllLte digital island. Only write to this register when FSASYNCBUSBUSY returns 0
  [31] READ — When 1, a read transaction is initiated. When the event COMPLETETRANS is set, read back this register
  [27:16] FSCOMMANDADDR — Address for the async interface. ALWAYS 0x84.
    132=FSM_PVT1_MODE_ADDR (ALWAYS 0x84.)
  [7:0] FSM_PVT1_MODE — For how long to be in the PVT1 state. It is multiplied with FSM_PVT1_NR_GEARS.
0x400 FSCOMMAND_FSM_PVT1_NR_GEARS reset 0x8C0004 (alternate view of FSCOMMAND_ANA_ISOLATION) — Send or receive command directly to/from the AdPllLte digital island. Only write to this register when FSASYNCBUSBUSY returns 0
  [31] READ — When 1, a read transaction is initiated. When the event COMPLETETRANS is set, read back this register
  [27:16] FSCOMMANDADDR — Address for the async interface. ALWAYS 0x8C.
    140=FSM_PVT1_NR_GEARS_ADDR (ALWAYS 0x8C.)
  [3:0] FSM_PVT1_NR_GEARS — The start value for the gear in NormPvt in PVT1 state. Used both in AdPllFsm and AdPllNormPvt. It affects how long we will be in the PVT1 state
0x400 FSCOMMAND_FSM_PVT2_MODE reset 0x880020 (alternate view of FSCOMMAND_ANA_ISOLATION) — Send or receive command directly to/from the AdPllLte digital island. Only write to this register when FSASYNCBUSBUSY returns 0
  [31] READ — When 1, a read transaction is initiated. When the event COMPLETETRANS is set, read back this register
  [27:16] FSCOMMANDADDR — Address for the async interface. ALWAYS 0x88.
    136=FSM_PVT2_MODE_ADDR (ALWAYS 0x88.)
  [7:0] FSM_PVT2_MODE — For how long to be in the PVT2 state. It is multiplied with FSM_PVT2_NR_GEARS.
